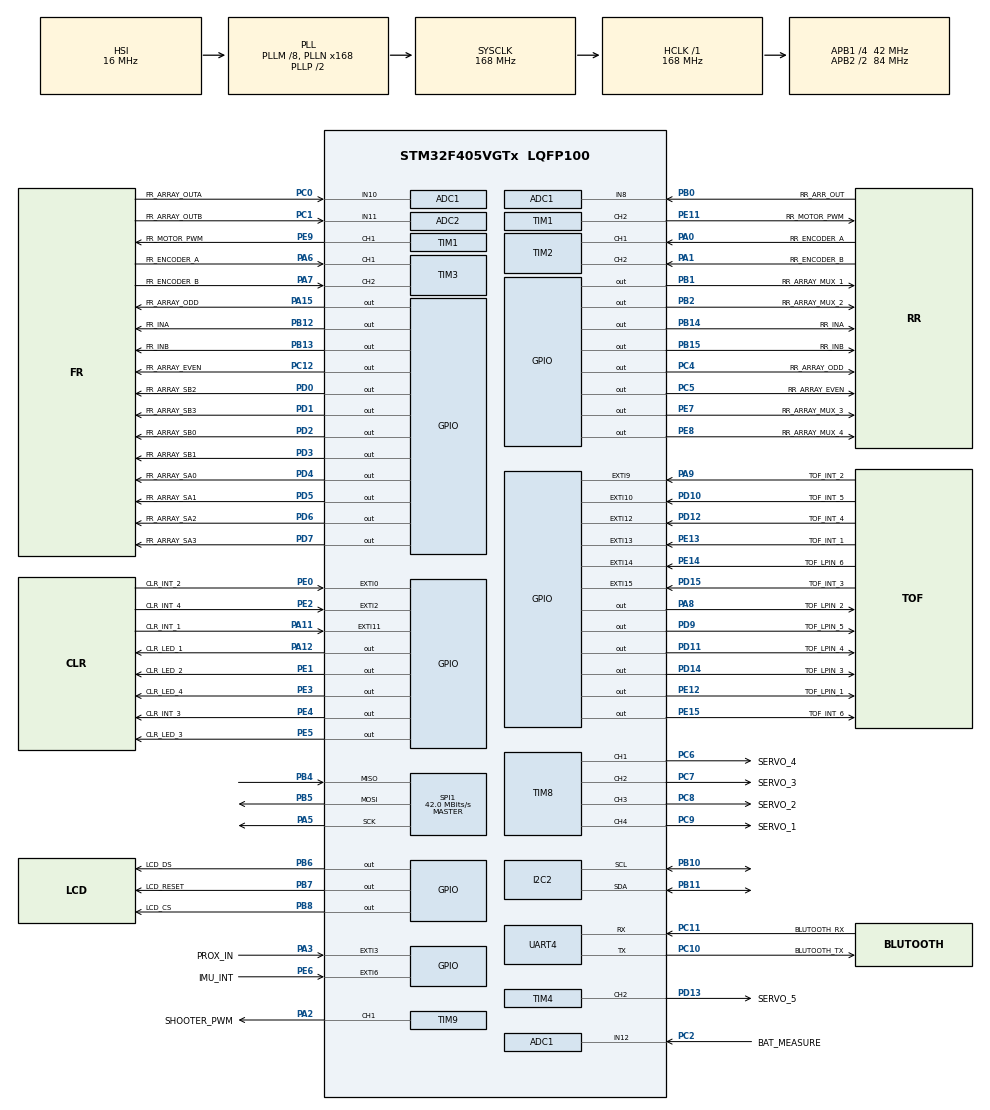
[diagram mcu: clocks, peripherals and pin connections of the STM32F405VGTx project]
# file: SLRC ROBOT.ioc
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ADC1.Channel-1\#ChannelRegularConversion=ADC_CHANNEL_8
ADC1.NbrOfConversionFlag=1
ADC1.Rank-1\#ChannelRegularConversion=1
ADC1.SamplingTime-1\#ChannelRegularConversion=ADC_SAMPLETIME_3CYCLES
ADC1.master=1
ADC2.Channel-1\#ChannelRegularConversion=ADC_CHANNEL_11
ADC2.NbrOfConversionFlag=1
ADC2.Rank-1\#ChannelRegularConversion=1
ADC2.SamplingTime-1\#ChannelRegularConversion=ADC_SAMPLETIME_3CYCLES
Mcu.Family=STM32F4
Mcu.Name=STM32F405VGTx
Mcu.Package=LQFP100
NVIC.PriorityGroup=NVIC_PRIORITYGROUP_4
PA0-WKUP.GPIO_Label=RR_ENCODER_A
PA0-WKUP.Signal=S_TIM2_CH1_ETR
PA1.GPIO_Label=RR_ENCODER_B
PA1.Signal=S_TIM2_CH2
PA11.GPIO_Label=CLR_INT_1
PA11.Signal=GPXTI11
PA12.GPIO_Label=CLR_LED_1
PA12.Signal=GPIO_Output
PA13.Mode=Trace_Asynchronous_SW
PA13.Signal=SYS_JTMS-SWDIO
PA14.Mode=Trace_Asynchronous_SW
PA14.Signal=SYS_JTCK-SWCLK
PA15.GPIO_Label=FR_ARRAY_ODD
PA15.Signal=GPIO_Output
PA2.GPIO_Label=SHOOTER_PWM
PA2.Signal=S_TIM9_CH1
PA3.GPIO_Label=PROX_IN
PA3.Signal=GPXTI3
PA5.Mode=Full_Duplex_Master
PA5.Signal=SPI1_SCK
PA6.GPIO_Label=FR_ENCODER_A
PA6.Signal=S_TIM3_CH1
PA7.GPIO_Label=FR_ENCODER_B
PA7.Signal=S_TIM3_CH2
PA8.GPIO_Label=TOF_LPIN_2
PA8.Signal=GPIO_Output
PA9.GPIO_Label=TOF_INT_2
PA9.Signal=GPXTI9
PB0.GPIO_Label=RR_ARR_OUT
PB0.Signal=ADCx_IN8
PB1.GPIO_Label=RR_ARRAY_MUX_1
PB1.Signal=GPIO_Output
PB10.GPIO_Pu=GPIO_PULLUP
PB10.Mode=I2C
PB10.Signal=I2C2_SCL
PB11.GPIO_Pu=GPIO_PULLUP
PB11.Mode=I2C
PB11.Signal=I2C2_SDA
PB12.GPIO_Label=FR_INA
PB12.Signal=GPIO_Output
PB13.GPIO_Label=FR_INB
PB13.Signal=GPIO_Output
PB14.GPIO_Label=RR_INA
PB14.Signal=GPIO_Output
PB15.GPIO_Label=RR_INB
PB15.Signal=GPIO_Output
PB2.GPIO_Label=RR_ARRAY_MUX_2
PB2.Signal=GPIO_Output
PB3.Mode=Trace_Asynchronous_SW
PB3.Signal=SYS_JTDO-SWO
PB4.Mode=Full_Duplex_Master
PB4.Signal=SPI1_MISO
PB5.Mode=Full_Duplex_Master
PB5.Signal=SPI1_MOSI
PB6.GPIO_Label=LCD_DS
PB6.Signal=GPIO_Output
PB7.GPIO_Label=LCD_RESET
PB7.Signal=GPIO_Output
PB8.GPIO_Label=LCD_CS
PB8.Signal=GPIO_Output
PC0.GPIO_Label=FR_ARRAY_OUTA
PC0.Signal=ADCx_IN10
PC1.GPIO_Label=FR_ARRAY_OUTB
PC1.Signal=ADCx_IN11
PC10.GPIO_Label=BLUTOOTH_TX
PC10.Mode=Asynchronous
PC10.Signal=UART4_TX
PC11.GPIO_Label=BLUTOOTH_RX
PC11.Mode=Asynchronous
PC11.Signal=UART4_RX
PC12.GPIO_Label=FR_ARRAY_EVEN
PC12.Signal=GPIO_Output
PC2.GPIO_Label=BAT_MEASURE
PC2.Signal=ADCx_IN12
PC4.GPIO_Label=RR_ARRAY_ODD
PC4.Signal=GPIO_Output
PC5.GPIO_Label=RR_ARRAY_EVEN
PC5.Signal=GPIO_Output
PC6.GPIO_Label=SERVO_4
PC6.Signal=S_TIM8_CH1
PC7.GPIO_Label=SERVO_3
PC7.Signal=S_TIM8_CH2
PC8.GPIO_Label=SERVO_2
PC8.Signal=S_TIM8_CH3
PC9.GPIO_Label=SERVO_1
PC9.Signal=S_TIM8_CH4
PD0.GPIO_Label=FR_ARRAY_SB2
PD0.Signal=GPIO_Output
PD1.GPIO_Label=FR_ARRAY_SB3
PD1.Signal=GPIO_Output
PD10.GPIO_Label=TOF_INT_5
PD10.Signal=GPXTI10
PD11.GPIO_Label=TOF_LPIN_4
PD11.Signal=GPIO_Output
PD12.GPIO_Label=TOF_INT_4
PD12.Signal=GPXTI12
PD13.GPIO_Label=SERVO_5
PD13.Signal=S_TIM4_CH2
PD14.GPIO_Label=TOF_LPIN_3
PD14.Signal=GPIO_Output
PD15.GPIO_Label=TOF_INT_3
PD15.Signal=GPXTI15
PD2.GPIO_Label=FR_ARRAY_SB0
PD2.Signal=GPIO_Output
PD3.GPIO_Label=FR_ARRAY_SB1
PD3.Signal=GPIO_Output
PD4.GPIO_Label=FR_ARRAY_SA0
PD4.Signal=GPIO_Output
PD5.GPIO_Label=FR_ARRAY_SA1
PD5.Signal=GPIO_Output
PD6.GPIO_Label=FR_ARRAY_SA2
PD6.Signal=GPIO_Output
PD7.GPIO_Label=FR_ARRAY_SA3
PD7.Signal=GPIO_Output
PD9.GPIO_Label=TOF_LPIN_5
PD9.Signal=GPIO_Output
PE0.GPIO_Label=CLR_INT_2
PE0.Signal=GPXTI0
PE1.GPIO_Label=CLR_LED_2
PE1.Signal=GPIO_Output
PE11.GPIO_Label=RR_MOTOR_PWM
PE11.Signal=S_TIM1_CH2
PE12.GPIO_Label=TOF_LPIN_1
PE12.Signal=GPIO_Output
PE13.GPIO_Label=TOF_INT_1
PE13.Signal=GPXTI13
PE14.GPIO_Label=TOF_LPIN_6
PE14.Signal=GPXTI14
PE15.GPIO_Label=TOF_INT_6
PE15.Signal=GPIO_Output
PE2.GPIO_Label=CLR_INT_4
PE2.Signal=GPXTI2
PE3.GPIO_Label=CLR_LED_4
PE3.Signal=GPIO_Output
PE4.GPIO_Label=CLR_INT_3
PE4.Signal=GPIO_Output
PE5.GPIO_Label=CLR_LED_3
PE5.Signal=GPIO_Output
PE6.GPIO_Label=IMU_INT
PE6.Signal=GPXTI6
PE7.GPIO_Label=RR_ARRAY_MUX_3
PE7.Signal=GPIO_Output
PE8.GPIO_Label=RR_ARRAY_MUX_4
PE8.Signal=GPIO_Output
PE9.GPIO_Label=FR_MOTOR_PWM
PE9.Signal=S_TIM1_CH1
PH0-OSC_IN.Mode=HSE-External-Oscillator
PH0-OSC_IN.Signal=RCC_OSC_IN
PH1-OSC_OUT.Mode=HSE-External-Oscillator
PH1-OSC_OUT.Signal=RCC_OSC_OUT
ProjectManager.HeapSize=0x200
ProjectManager.StackSize=0x400
ProjectManager.TargetToolchain=STM32CubeIDE
RCC.48MHZClocksFreq_Value=84000000
RCC.AHBFreq_Value=168000000
RCC.APB1CLKDivider=RCC_HCLK_DIV4
RCC.APB1Freq_Value=42000000
RCC.APB1TimFreq_Value=84000000
RCC.APB2CLKDivider=RCC_HCLK_DIV2
RCC.APB2Freq_Value=84000000
RCC.APB2TimFreq_Value=168000000
RCC.CortexFreq_Value=168000000
RCC.HCLKFreq_Value=168000000
RCC.HSE_VALUE=24000000
RCC.HSI_VALUE=16000000
RCC.LSE_VALUE=32768
RCC.PLLM=8
RCC.PLLN=168
RCC.SYSCLKFreq_VALUE=168000000
RCC.SYSCLKSource=RCC_SYSCLKSOURCE_PLLCLK
RCC.VCOOutputFreq_Value=336000000
SH.ADCx_IN10.0=ADC1_IN10,IN10
SH.ADCx_IN11.0=ADC2_IN11,IN11
SH.ADCx_IN12.0=ADC1_IN12,IN12
SH.ADCx_IN8.0=ADC1_IN8,IN8
SH.S_TIM1_CH1.0=TIM1_CH1,PWM Generation1 CH1
SH.S_TIM1_CH2.0=TIM1_CH2,PWM Generation2 CH2
SH.S_TIM2_CH1_ETR.0=TIM2_CH1,Encoder_Interface
SH.S_TIM2_CH2.0=TIM2_CH2,Encoder_Interface
SH.S_TIM3_CH1.0=TIM3_CH1,Encoder_Interface
SH.S_TIM3_CH2.0=TIM3_CH2,Encoder_Interface
SH.S_TIM4_CH2.0=TIM4_CH2,PWM Generation2 CH2
SH.S_TIM8_CH1.0=TIM8_CH1,PWM Generation1 CH1
SH.S_TIM8_CH2.0=TIM8_CH2,PWM Generation2 CH2
SH.S_TIM8_CH3.0=TIM8_CH3,PWM Generation3 CH3
SH.S_TIM8_CH4.0=TIM8_CH4,PWM Generation4 CH4
SH.S_TIM9_CH1.0=TIM9_CH1,PWM Generation1 CH1
SPI1.CalculateBaudRate=42.0 MBits/s
SPI1.Direction=SPI_DIRECTION_2LINES
SPI1.Mode=SPI_MODE_MASTER
SPI1.VirtualType=VM_MASTER
TIM1.Channel-PWM\ Generation1\ CH1=TIM_CHANNEL_1
TIM1.Channel-PWM\ Generation2\ CH2=TIM_CHANNEL_2
TIM3.EncoderMode=TIM_ENCODERMODE_TI12
TIM4.Channel-PWM\ Generation2\ CH2=TIM_CHANNEL_2
TIM8.Channel-PWM\ Generation1\ CH1=TIM_CHANNEL_1
TIM8.Channel-PWM\ Generation2\ CH2=TIM_CHANNEL_2
TIM8.Channel-PWM\ Generation3\ CH3=TIM_CHANNEL_3
TIM8.Channel-PWM\ Generation4\ CH4=TIM_CHANNEL_4
TIM9.Channel-PWM\ Generation1\ CH1=TIM_CHANNEL_1
UART4.VirtualMode=Asynchronous
VP_TIM1_VS_ClockSourceINT.Mode=Internal
VP_TIM4_VS_ClockSourceINT.Mode=Internal
VP_TIM8_VS_ClockSourceINT.Mode=Internal
VP_TIM9_VS_ClockSourceINT.Mode=Internal
board=custom

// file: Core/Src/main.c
/* USER CODE BEGIN Header */
/**
  ******************************************************************************
  * @file           : main.c
  * @brief          : Main program body
  ******************************************************************************
  * @attention
  *
  * Copyright (c) 2024 STMicroelectronics.
  * All rights reserved.
  *
  * This software is licensed under terms that can be found in the LICENSE file
  * in the root directory of this software component.
  * If no LICENSE file comes with this software, it is provided AS-IS.
  *
  ******************************************************************************
  */
/* USER CODE END Header */
#include "main.h"

/* USER CODE BEGIN Includes */
#include "TPS55288.h"
#include "stm32f4xx_hal.h"
/* USER CODE END Includes */

ADC_HandleTypeDef hadc1;
ADC_HandleTypeDef hadc2;

I2C_HandleTypeDef hi2c2;

SPI_HandleTypeDef hspi1;

TIM_HandleTypeDef htim1;
TIM_HandleTypeDef htim2;
TIM_HandleTypeDef htim3;
TIM_HandleTypeDef htim4;
TIM_HandleTypeDef htim8;
TIM_HandleTypeDef htim9;

UART_HandleTypeDef huart4;

/* USER CODE BEGIN PV */
TPS55288 BuckBoost;
HAL_StatusTypeDef result;
uint8_t TX_Buffer [] = "A" ; // DATA to send
/* USER CODE END PV */

void SystemClock_Config(void);
static void MX_GPIO_Init(void);
static void MX_ADC1_Init(void);
static void MX_I2C2_Init(void);
static void MX_TIM1_Init(void);
static void MX_TIM3_Init(void);
static void MX_TIM4_Init(void);
static void MX_TIM8_Init(void);
static void MX_TIM9_Init(void);
static void MX_UART4_Init(void);
static void MX_SPI1_Init(void);
static void MX_ADC2_Init(void);
static void MX_TIM2_Init(void);

int main(void)
{

  /* MCU Configuration--------------------------------------------------------*/

  /* Reset of all peripherals, Initializes the Flash interface and the Systick. */
  HAL_Init();

  /* Configure the system clock */
  SystemClock_Config();

  /* Initialize all configured peripherals */
  MX_GPIO_Init();
  MX_ADC1_Init();
  MX_I2C2_Init();
  MX_TIM1_Init();
  MX_TIM3_Init();
  MX_TIM4_Init();
  MX_TIM8_Init();
  MX_TIM9_Init();
  MX_UART4_Init();
  MX_SPI1_Init();
  MX_ADC2_Init();
  MX_TIM2_Init();
  /* USER CODE BEGIN 2 */

#define ADDRESS_TO 0x40

  /* USER CODE END 2 */

  /* Infinite loop */
  while (1)
  {

    /* USER CODE BEGIN 3 */
//	  uint8_t status = TPS55288_Initialize(&BuckBoost, &hi2c2);
	  uint8_t command;
	  uint8_t config;
	  uint8_t output;
	  command = 0x03;
	  config = 0x00;
//	  HAL_I2C_Mem_Write(&hi2c2, ADDRESS_TO, command, 1, &config, 1, 10);
//	  HAL_I2C_Mem_Write(&hi2c2,TPS55288_I2C_ADDR,command,1,&config, 1 ,10); //Sending in Blocking mode
 // for the return value from HAL function calls

		result = HAL_I2C_IsDeviceReady( &hi2c2, 0x40<<1, 10, 1000 );
	  HAL_Delay(100);
	  HAL_GPIO_WritePin(CLR_LED_3_GPIO_Port, CLR_LED_3_Pin, GPIO_PIN_SET);
	  HAL_Delay(1500);
	  HAL_GPIO_WritePin(CLR_LED_3_GPIO_Port, CLR_LED_3_Pin, GPIO_PIN_RESET);
	  HAL_Delay(1500);
  }
  /* USER CODE END 3 */
}

void SystemClock_Config(void)
{
  RCC_OscInitTypeDef RCC_OscInitStruct = {0};
  RCC_ClkInitTypeDef RCC_ClkInitStruct = {0};

  /** Configure the main internal regulator output voltage
  */
  __HAL_RCC_PWR_CLK_ENABLE();
  __HAL_PWR_VOLTAGESCALING_CONFIG(PWR_REGULATOR_VOLTAGE_SCALE1);

  /** Initializes the RCC Oscillators according to the specified parameters
  * in the RCC_OscInitTypeDef structure.
  */
  RCC_OscInitStruct.OscillatorType = RCC_OSCILLATORTYPE_HSI;
  RCC_OscInitStruct.HSIState = RCC_HSI_ON;
  RCC_OscInitStruct.HSICalibrationValue = RCC_HSICALIBRATION_DEFAULT;
  RCC_OscInitStruct.PLL.PLLState = RCC_PLL_ON;
  RCC_OscInitStruct.PLL.PLLSource = RCC_PLLSOURCE_HSI;
  RCC_OscInitStruct.PLL.PLLM = 8;
  RCC_OscInitStruct.PLL.PLLN = 168;
  RCC_OscInitStruct.PLL.PLLP = RCC_PLLP_DIV2;
  RCC_OscInitStruct.PLL.PLLQ = 4;
  if (HAL_RCC_OscConfig(&RCC_OscInitStruct) != HAL_OK)
  {
    Error_Handler();
  }

  /** Initializes the CPU, AHB and APB buses clocks
  */
  RCC_ClkInitStruct.ClockType = RCC_CLOCKTYPE_HCLK|RCC_CLOCKTYPE_SYSCLK
                              |RCC_CLOCKTYPE_PCLK1|RCC_CLOCKTYPE_PCLK2;
  RCC_ClkInitStruct.SYSCLKSource = RCC_SYSCLKSOURCE_PLLCLK;
  RCC_ClkInitStruct.AHBCLKDivider = RCC_SYSCLK_DIV1;
  RCC_ClkInitStruct.APB1CLKDivider = RCC_HCLK_DIV4;
  RCC_ClkInitStruct.APB2CLKDivider = RCC_HCLK_DIV2;

  if (HAL_RCC_ClockConfig(&RCC_ClkInitStruct, FLASH_LATENCY_5) != HAL_OK)
  {
    Error_Handler();
  }
}

static void MX_ADC1_Init(void)
{

  ADC_ChannelConfTypeDef sConfig = {0};

  /** Configure the global features of the ADC (Clock, Resolution, Data Alignment and number of conversion)
  */
  hadc1.Instance = ADC1;
  hadc1.Init.ClockPrescaler = ADC_CLOCK_SYNC_PCLK_DIV4;
  hadc1.Init.Resolution = ADC_RESOLUTION_12B;
  hadc1.Init.ScanConvMode = DISABLE;
  hadc1.Init.ContinuousConvMode = DISABLE;
  hadc1.Init.DiscontinuousConvMode = DISABLE;
  hadc1.Init.ExternalTrigConvEdge = ADC_EXTERNALTRIGCONVEDGE_NONE;
  hadc1.Init.ExternalTrigConv = ADC_SOFTWARE_START;
  hadc1.Init.DataAlign = ADC_DATAALIGN_RIGHT;
  hadc1.Init.NbrOfConversion = 1;
  hadc1.Init.DMAContinuousRequests = DISABLE;
  hadc1.Init.EOCSelection = ADC_EOC_SINGLE_CONV;
  if (HAL_ADC_Init(&hadc1) != HAL_OK)
  {
    Error_Handler();
  }

  /** Configure for the selected ADC regular channel its corresponding rank in the sequencer and its sample time.
  */
  sConfig.Channel = ADC_CHANNEL_8;
  sConfig.Rank = 1;
  sConfig.SamplingTime = ADC_SAMPLETIME_3CYCLES;
  if (HAL_ADC_ConfigChannel(&hadc1, &sConfig) != HAL_OK)
  {
    Error_Handler();
  }

}

static void MX_ADC2_Init(void)
{

  ADC_ChannelConfTypeDef sConfig = {0};

  /** Configure the global features of the ADC (Clock, Resolution, Data Alignment and number of conversion)
  */
  hadc2.Instance = ADC2;
  hadc2.Init.ClockPrescaler = ADC_CLOCK_SYNC_PCLK_DIV4;
  hadc2.Init.Resolution = ADC_RESOLUTION_12B;
  hadc2.Init.ScanConvMode = DISABLE;
  hadc2.Init.ContinuousConvMode = DISABLE;
  hadc2.Init.DiscontinuousConvMode = DISABLE;
  hadc2.Init.ExternalTrigConvEdge = ADC_EXTERNALTRIGCONVEDGE_NONE;
  hadc2.Init.ExternalTrigConv = ADC_SOFTWARE_START;
  hadc2.Init.DataAlign = ADC_DATAALIGN_RIGHT;
  hadc2.Init.NbrOfConversion = 1;
  hadc2.Init.DMAContinuousRequests = DISABLE;
  hadc2.Init.EOCSelection = ADC_EOC_SINGLE_CONV;
  if (HAL_ADC_Init(&hadc2) != HAL_OK)
  {
    Error_Handler();
  }

  /** Configure for the selected ADC regular channel its corresponding rank in the sequencer and its sample time.
  */
  sConfig.Channel = ADC_CHANNEL_11;
  sConfig.Rank = 1;
  sConfig.SamplingTime = ADC_SAMPLETIME_3CYCLES;
  if (HAL_ADC_ConfigChannel(&hadc2, &sConfig) != HAL_OK)
  {
    Error_Handler();
  }

}

static void MX_I2C2_Init(void)
{

  hi2c2.Instance = I2C2;
  hi2c2.Init.ClockSpeed = 100000;
  hi2c2.Init.DutyCycle = I2C_DUTYCYCLE_2;
  hi2c2.Init.OwnAddress1 = 0;
  hi2c2.Init.AddressingMode = I2C_ADDRESSINGMODE_7BIT;
  hi2c2.Init.DualAddressMode = I2C_DUALADDRESS_DISABLE;
  hi2c2.Init.OwnAddress2 = 0;
  hi2c2.Init.GeneralCallMode = I2C_GENERALCALL_DISABLE;
  hi2c2.Init.NoStretchMode = I2C_NOSTRETCH_DISABLE;
  if (HAL_I2C_Init(&hi2c2) != HAL_OK)
  {
    Error_Handler();
  }

}

static void MX_SPI1_Init(void)
{

  /* SPI1 parameter configuration*/
  hspi1.Instance = SPI1;
  hspi1.Init.Mode = SPI_MODE_MASTER;
  hspi1.Init.Direction = SPI_DIRECTION_2LINES;
  hspi1.Init.DataSize = SPI_DATASIZE_8BIT;
  hspi1.Init.CLKPolarity = SPI_POLARITY_LOW;
  hspi1.Init.CLKPhase = SPI_PHASE_1EDGE;
  hspi1.Init.NSS = SPI_NSS_SOFT;
  hspi1.Init.BaudRatePrescaler = SPI_BAUDRATEPRESCALER_2;
  hspi1.Init.FirstBit = SPI_FIRSTBIT_MSB;
  hspi1.Init.TIMode = SPI_TIMODE_DISABLE;
  hspi1.Init.CRCCalculation = SPI_CRCCALCULATION_DISABLE;
  hspi1.Init.CRCPolynomial = 10;
  if (HAL_SPI_Init(&hspi1) != HAL_OK)
  {
    Error_Handler();
  }

}

static void MX_TIM1_Init(void)
{

  TIM_ClockConfigTypeDef sClockSourceConfig = {0};
  TIM_MasterConfigTypeDef sMasterConfig = {0};
  TIM_OC_InitTypeDef sConfigOC = {0};
  TIM_BreakDeadTimeConfigTypeDef sBreakDeadTimeConfig = {0};

  htim1.Instance = TIM1;
  htim1.Init.Prescaler = 0;
  htim1.Init.CounterMode = TIM_COUNTERMODE_UP;
  htim1.Init.Period = 65535;
  htim1.Init.ClockDivision = TIM_CLOCKDIVISION_DIV1;
  htim1.Init.RepetitionCounter = 0;
  htim1.Init.AutoReloadPreload = TIM_AUTORELOAD_PRELOAD_DISABLE;
  if (HAL_TIM_Base_Init(&htim1) != HAL_OK)
  {
    Error_Handler();
  }
  sClockSourceConfig.ClockSource = TIM_CLOCKSOURCE_INTERNAL;
  if (HAL_TIM_ConfigClockSource(&htim1, &sClockSourceConfig) != HAL_OK)
  {
    Error_Handler();
  }
  if (HAL_TIM_PWM_Init(&htim1) != HAL_OK)
  {
    Error_Handler();
  }
  sMasterConfig.MasterOutputTrigger = TIM_TRGO_RESET;
  sMasterConfig.MasterSlaveMode = TIM_MASTERSLAVEMODE_DISABLE;
  if (HAL_TIMEx_MasterConfigSynchronization(&htim1, &sMasterConfig) != HAL_OK)
  {
    Error_Handler();
  }
  sConfigOC.OCMode = TIM_OCMODE_PWM1;
  sConfigOC.Pulse = 0;
  sConfigOC.OCPolarity = TIM_OCPOLARITY_HIGH;
  sConfigOC.OCNPolarity = TIM_OCNPOLARITY_HIGH;
  sConfigOC.OCFastMode = TIM_OCFAST_DISABLE;
  sConfigOC.OCIdleState = TIM_OCIDLESTATE_RESET;
  sConfigOC.OCNIdleState = TIM_OCNIDLESTATE_RESET;
  if (HAL_TIM_PWM_ConfigChannel(&htim1, &sConfigOC, TIM_CHANNEL_1) != HAL_OK)
  {
    Error_Handler();
  }
  if (HAL_TIM_PWM_ConfigChannel(&htim1, &sConfigOC, TIM_CHANNEL_2) != HAL_OK)
  {
    Error_Handler();
  }
  sBreakDeadTimeConfig.OffStateRunMode = TIM_OSSR_DISABLE;
  sBreakDeadTimeConfig.OffStateIDLEMode = TIM_OSSI_DISABLE;
  sBreakDeadTimeConfig.LockLevel = TIM_LOCKLEVEL_OFF;
  sBreakDeadTimeConfig.DeadTime = 0;
  sBreakDeadTimeConfig.BreakState = TIM_BREAK_DISABLE;
  sBreakDeadTimeConfig.BreakPolarity = TIM_BREAKPOLARITY_HIGH;
  sBreakDeadTimeConfig.AutomaticOutput = TIM_AUTOMATICOUTPUT_DISABLE;
  if (HAL_TIMEx_ConfigBreakDeadTime(&htim1, &sBreakDeadTimeConfig) != HAL_OK)
  {
    Error_Handler();
  }
  HAL_TIM_MspPostInit(&htim1);

}

static void MX_TIM2_Init(void)
{

  TIM_Encoder_InitTypeDef sConfig = {0};
  TIM_MasterConfigTypeDef sMasterConfig = {0};

  htim2.Instance = TIM2;
  htim2.Init.Prescaler = 0;
  htim2.Init.CounterMode = TIM_COUNTERMODE_UP;
  htim2.Init.Period = 4294967295;
  htim2.Init.ClockDivision = TIM_CLOCKDIVISION_DIV1;
  htim2.Init.AutoReloadPreload = TIM_AUTORELOAD_PRELOAD_DISABLE;
  sConfig.EncoderMode = TIM_ENCODERMODE_TI1;
  sConfig.IC1Polarity = TIM_ICPOLARITY_RISING;
  sConfig.IC1Selection = TIM_ICSELECTION_DIRECTTI;
  sConfig.IC1Prescaler = TIM_ICPSC_DIV1;
  sConfig.IC1Filter = 0;
  sConfig.IC2Polarity = TIM_ICPOLARITY_RISING;
  sConfig.IC2Selection = TIM_ICSELECTION_DIRECTTI;
  sConfig.IC2Prescaler = TIM_ICPSC_DIV1;
  sConfig.IC2Filter = 0;
  if (HAL_TIM_Encoder_Init(&htim2, &sConfig) != HAL_OK)
  {
    Error_Handler();
  }
  sMasterConfig.MasterOutputTrigger = TIM_TRGO_RESET;
  sMasterConfig.MasterSlaveMode = TIM_MASTERSLAVEMODE_DISABLE;
  if (HAL_TIMEx_MasterConfigSynchronization(&htim2, &sMasterConfig) != HAL_OK)
  {
    Error_Handler();
  }

}

static void MX_TIM3_Init(void)
{

  TIM_Encoder_InitTypeDef sConfig = {0};
  TIM_MasterConfigTypeDef sMasterConfig = {0};

  htim3.Instance = TIM3;
  htim3.Init.Prescaler = 0;
  htim3.Init.CounterMode = TIM_COUNTERMODE_UP;
  htim3.Init.Period = 65535;
  htim3.Init.ClockDivision = TIM_CLOCKDIVISION_DIV1;
  htim3.Init.AutoReloadPreload = TIM_AUTORELOAD_PRELOAD_DISABLE;
  sConfig.EncoderMode = TIM_ENCODERMODE_TI12;
  sConfig.IC1Polarity = TIM_ICPOLARITY_RISING;
  sConfig.IC1Selection = TIM_ICSELECTION_DIRECTTI;
  sConfig.IC1Prescaler = TIM_ICPSC_DIV1;
  sConfig.IC1Filter = 0;
  sConfig.IC2Polarity = TIM_ICPOLARITY_RISING;
  sConfig.IC2Selection = TIM_ICSELECTION_DIRECTTI;
  sConfig.IC2Prescaler = TIM_ICPSC_DIV1;
  sConfig.IC2Filter = 0;
  if (HAL_TIM_Encoder_Init(&htim3, &sConfig) != HAL_OK)
  {
    Error_Handler();
  }
  sMasterConfig.MasterOutputTrigger = TIM_TRGO_RESET;
  sMasterConfig.MasterSlaveMode = TIM_MASTERSLAVEMODE_DISABLE;
  if (HAL_TIMEx_MasterConfigSynchronization(&htim3, &sMasterConfig) != HAL_OK)
  {
    Error_Handler();
  }

}

static void MX_TIM4_Init(void)
{

  TIM_ClockConfigTypeDef sClockSourceConfig = {0};
  TIM_MasterConfigTypeDef sMasterConfig = {0};
  TIM_OC_InitTypeDef sConfigOC = {0};

  htim4.Instance = TIM4;
  htim4.Init.Prescaler = 0;
  htim4.Init.CounterMode = TIM_COUNTERMODE_UP;
  htim4.Init.Period = 65535;
  htim4.Init.ClockDivision = TIM_CLOCKDIVISION_DIV1;
  htim4.Init.AutoReloadPreload = TIM_AUTORELOAD_PRELOAD_DISABLE;
  if (HAL_TIM_Base_Init(&htim4) != HAL_OK)
  {
    Error_Handler();
  }
  sClockSourceConfig.ClockSource = TIM_CLOCKSOURCE_INTERNAL;
  if (HAL_TIM_ConfigClockSource(&htim4, &sClockSourceConfig) != HAL_OK)
  {
    Error_Handler();
  }
  if (HAL_TIM_PWM_Init(&htim4) != HAL_OK)
  {
    Error_Handler();
  }
  sMasterConfig.MasterOutputTrigger = TIM_TRGO_RESET;
  sMasterConfig.MasterSlaveMode = TIM_MASTERSLAVEMODE_DISABLE;
  if (HAL_TIMEx_MasterConfigSynchronization(&htim4, &sMasterConfig) != HAL_OK)
  {
    Error_Handler();
  }
  sConfigOC.OCMode = TIM_OCMODE_PWM1;
  sConfigOC.Pulse = 0;
  sConfigOC.OCPolarity = TIM_OCPOLARITY_HIGH;
  sConfigOC.OCFastMode = TIM_OCFAST_DISABLE;
  if (HAL_TIM_PWM_ConfigChannel(&htim4, &sConfigOC, TIM_CHANNEL_2) != HAL_OK)
  {
    Error_Handler();
  }
  HAL_TIM_MspPostInit(&htim4);

}

static void MX_TIM8_Init(void)
{

  TIM_ClockConfigTypeDef sClockSourceConfig = {0};
  TIM_MasterConfigTypeDef sMasterConfig = {0};
  TIM_OC_InitTypeDef sConfigOC = {0};
  TIM_BreakDeadTimeConfigTypeDef sBreakDeadTimeConfig = {0};

  htim8.Instance = TIM8;
  htim8.Init.Prescaler = 0;
  htim8.Init.CounterMode = TIM_COUNTERMODE_UP;
  htim8.Init.Period = 65535;
  htim8.Init.ClockDivision = TIM_CLOCKDIVISION_DIV1;
  htim8.Init.RepetitionCounter = 0;
  htim8.Init.AutoReloadPreload = TIM_AUTORELOAD_PRELOAD_DISABLE;
  if (HAL_TIM_Base_Init(&htim8) != HAL_OK)
  {
    Error_Handler();
  }
  sClockSourceConfig.ClockSource = TIM_CLOCKSOURCE_INTERNAL;
  if (HAL_TIM_ConfigClockSource(&htim8, &sClockSourceConfig) != HAL_OK)
  {
    Error_Handler();
  }
  if (HAL_TIM_PWM_Init(&htim8) != HAL_OK)
  {
    Error_Handler();
  }
  sMasterConfig.MasterOutputTrigger = TIM_TRGO_RESET;
  sMasterConfig.MasterSlaveMode = TIM_MASTERSLAVEMODE_DISABLE;
  if (HAL_TIMEx_MasterConfigSynchronization(&htim8, &sMasterConfig) != HAL_OK)
  {
    Error_Handler();
  }
  sConfigOC.OCMode = TIM_OCMODE_PWM1;
  sConfigOC.Pulse = 0;
  sConfigOC.OCPolarity = TIM_OCPOLARITY_HIGH;
  sConfigOC.OCNPolarity = TIM_OCNPOLARITY_HIGH;
  sConfigOC.OCFastMode = TIM_OCFAST_DISABLE;
  sConfigOC.OCIdleState = TIM_OCIDLESTATE_RESET;
  sConfigOC.OCNIdleState = TIM_OCNIDLESTATE_RESET;
  if (HAL_TIM_PWM_ConfigChannel(&htim8, &sConfigOC, TIM_CHANNEL_1) != HAL_OK)
  {
    Error_Handler();
  }
  if (HAL_TIM_PWM_ConfigChannel(&htim8, &sConfigOC, TIM_CHANNEL_2) != HAL_OK)
  {
    Error_Handler();
  }
  if (HAL_TIM_PWM_ConfigChannel(&htim8, &sConfigOC, TIM_CHANNEL_3) != HAL_OK)
  {
    Error_Handler();
  }
  if (HAL_TIM_PWM_ConfigChannel(&htim8, &sConfigOC, TIM_CHANNEL_4) != HAL_OK)
  {
    Error_Handler();
  }
  sBreakDeadTimeConfig.OffStateRunMode = TIM_OSSR_DISABLE;
  sBreakDeadTimeConfig.OffStateIDLEMode = TIM_OSSI_DISABLE;
  sBreakDeadTimeConfig.LockLevel = TIM_LOCKLEVEL_OFF;
  sBreakDeadTimeConfig.DeadTime = 0;
  sBreakDeadTimeConfig.BreakState = TIM_BREAK_DISABLE;
  sBreakDeadTimeConfig.BreakPolarity = TIM_BREAKPOLARITY_HIGH;
  sBreakDeadTimeConfig.AutomaticOutput = TIM_AUTOMATICOUTPUT_DISABLE;
  if (HAL_TIMEx_ConfigBreakDeadTime(&htim8, &sBreakDeadTimeConfig) != HAL_OK)
  {
    Error_Handler();
  }
  HAL_TIM_MspPostInit(&htim8);

}

static void MX_TIM9_Init(void)
{

  TIM_ClockConfigTypeDef sClockSourceConfig = {0};
  TIM_OC_InitTypeDef sConfigOC = {0};

  htim9.Instance = TIM9;
  htim9.Init.Prescaler = 0;
  htim9.Init.CounterMode = TIM_COUNTERMODE_UP;
  htim9.Init.Period = 65535;
  htim9.Init.ClockDivision = TIM_CLOCKDIVISION_DIV1;
  htim9.Init.AutoReloadPreload = TIM_AUTORELOAD_PRELOAD_DISABLE;
  if (HAL_TIM_Base_Init(&htim9) != HAL_OK)
  {
    Error_Handler();
  }
  sClockSourceConfig.ClockSource = TIM_CLOCKSOURCE_INTERNAL;
  if (HAL_TIM_ConfigClockSource(&htim9, &sClockSourceConfig) != HAL_OK)
  {
    Error_Handler();
  }
  if (HAL_TIM_PWM_Init(&htim9) != HAL_OK)
  {
    Error_Handler();
  }
  sConfigOC.OCMode = TIM_OCMODE_PWM1;
  sConfigOC.Pulse = 0;
  sConfigOC.OCPolarity = TIM_OCPOLARITY_HIGH;
  sConfigOC.OCFastMode = TIM_OCFAST_DISABLE;
  if (HAL_TIM_PWM_ConfigChannel(&htim9, &sConfigOC, TIM_CHANNEL_1) != HAL_OK)
  {
    Error_Handler();
  }
  HAL_TIM_MspPostInit(&htim9);

}

static void MX_UART4_Init(void)
{

  huart4.Instance = UART4;
  huart4.Init.BaudRate = 115200;
  huart4.Init.WordLength = UART_WORDLENGTH_8B;
  huart4.Init.StopBits = UART_STOPBITS_1;
  huart4.Init.Parity = UART_PARITY_NONE;
  huart4.Init.Mode = UART_MODE_TX_RX;
  huart4.Init.HwFlowCtl = UART_HWCONTROL_NONE;
  huart4.Init.OverSampling = UART_OVERSAMPLING_16;
  if (HAL_UART_Init(&huart4) != HAL_OK)
  {
    Error_Handler();
  }

}

static void MX_GPIO_Init(void)
{
  GPIO_InitTypeDef GPIO_InitStruct = {0};

  /* GPIO Ports Clock Enable */
  __HAL_RCC_GPIOE_CLK_ENABLE();
  __HAL_RCC_GPIOH_CLK_ENABLE();
  __HAL_RCC_GPIOC_CLK_ENABLE();
  __HAL_RCC_GPIOA_CLK_ENABLE();
  __HAL_RCC_GPIOB_CLK_ENABLE();
  __HAL_RCC_GPIOD_CLK_ENABLE();

  /*Configure GPIO pin Output Level */
  HAL_GPIO_WritePin(GPIOE, CLR_LED_4_Pin|CLR_INT_3_Pin|CLR_LED_3_Pin|RR_ARRAY_MUX_3_Pin
                          |RR_ARRAY_MUX_4_Pin|TOF_LPIN_1_Pin|TOF_INT_6_Pin|CLR_LED_2_Pin, GPIO_PIN_RESET);

  /*Configure GPIO pin Output Level */
  HAL_GPIO_WritePin(GPIOC, RR_ARRAY_ODD_Pin|RR_ARRAY_EVEN_Pin|FR_ARRAY_EVEN_Pin, GPIO_PIN_RESET);

  /*Configure GPIO pin Output Level */
  HAL_GPIO_WritePin(GPIOB, RR_ARRAY_MUX_1_Pin|RR_ARRAY_MUX_2_Pin|FR_INA_Pin|FR_INB_Pin
                          |RR_INA_Pin|RR_INB_Pin|LCD_DS_Pin|LCD_RESET_Pin
                          |LCD_CS_Pin, GPIO_PIN_RESET);

  /*Configure GPIO pin Output Level */
  HAL_GPIO_WritePin(GPIOD, TOF_LPIN_5_Pin|TOF_LPIN_4_Pin|TOF_LPIN_3_Pin|FR_ARRAY_SB2_Pin
                          |FR_ARRAY_SB3_Pin|FR_ARRAY_SB0_Pin|FR_ARRAY_SB1_Pin|FR_ARRAY_SA0_Pin
                          |FR_ARRAY_SA1_Pin|FR_ARRAY_SA2_Pin|FR_ARRAY_SA3_Pin, GPIO_PIN_RESET);

  /*Configure GPIO pin Output Level */
  HAL_GPIO_WritePin(GPIOA, TOF_LPIN_2_Pin|CLR_LED_1_Pin|FR_ARRAY_ODD_Pin, GPIO_PIN_RESET);

  /*Configure GPIO pins : CLR_INT_4_Pin IMU_INT_Pin TOF_INT_1_Pin TOF_LPIN_6_Pin
                           CLR_INT_2_Pin */
  GPIO_InitStruct.Pin = CLR_INT_4_Pin|IMU_INT_Pin|TOF_INT_1_Pin|TOF_LPIN_6_Pin
                          |CLR_INT_2_Pin;
  GPIO_InitStruct.Mode = GPIO_MODE_IT_RISING;
  GPIO_InitStruct.Pull = GPIO_NOPULL;
  HAL_GPIO_Init(GPIOE, &GPIO_InitStruct);

  /*Configure GPIO pins : CLR_LED_4_Pin CLR_INT_3_Pin CLR_LED_3_Pin RR_ARRAY_MUX_3_Pin
                           RR_ARRAY_MUX_4_Pin TOF_LPIN_1_Pin TOF_INT_6_Pin CLR_LED_2_Pin */
  GPIO_InitStruct.Pin = CLR_LED_4_Pin|CLR_INT_3_Pin|CLR_LED_3_Pin|RR_ARRAY_MUX_3_Pin
                          |RR_ARRAY_MUX_4_Pin|TOF_LPIN_1_Pin|TOF_INT_6_Pin|CLR_LED_2_Pin;
  GPIO_InitStruct.Mode = GPIO_MODE_OUTPUT_PP;
  GPIO_InitStruct.Pull = GPIO_NOPULL;
  GPIO_InitStruct.Speed = GPIO_SPEED_FREQ_LOW;
  HAL_GPIO_Init(GPIOE, &GPIO_InitStruct);

  /*Configure GPIO pins : PROX_IN_Pin TOF_INT_2_Pin CLR_INT_1_Pin */
  GPIO_InitStruct.Pin = PROX_IN_Pin|TOF_INT_2_Pin|CLR_INT_1_Pin;
  GPIO_InitStruct.Mode = GPIO_MODE_IT_RISING;
  GPIO_InitStruct.Pull = GPIO_NOPULL;
  HAL_GPIO_Init(GPIOA, &GPIO_InitStruct);

  /*Configure GPIO pins : RR_ARRAY_ODD_Pin RR_ARRAY_EVEN_Pin FR_ARRAY_EVEN_Pin */
  GPIO_InitStruct.Pin = RR_ARRAY_ODD_Pin|RR_ARRAY_EVEN_Pin|FR_ARRAY_EVEN_Pin;
  GPIO_InitStruct.Mode = GPIO_MODE_OUTPUT_PP;
  GPIO_InitStruct.Pull = GPIO_NOPULL;
  GPIO_InitStruct.Speed = GPIO_SPEED_FREQ_LOW;
  HAL_GPIO_Init(GPIOC, &GPIO_InitStruct);

  /*Configure GPIO pins : RR_ARRAY_MUX_1_Pin RR_ARRAY_MUX_2_Pin FR_INA_Pin FR_INB_Pin
                           RR_INA_Pin RR_INB_Pin LCD_DS_Pin LCD_RESET_Pin
                           LCD_CS_Pin */
  GPIO_InitStruct.Pin = RR_ARRAY_MUX_1_Pin|RR_ARRAY_MUX_2_Pin|FR_INA_Pin|FR_INB_Pin
                          |RR_INA_Pin|RR_INB_Pin|LCD_DS_Pin|LCD_RESET_Pin
                          |LCD_CS_Pin;
  GPIO_InitStruct.Mode = GPIO_MODE_OUTPUT_PP;
  GPIO_InitStruct.Pull = GPIO_NOPULL;
  GPIO_InitStruct.Speed = GPIO_SPEED_FREQ_LOW;
  HAL_GPIO_Init(GPIOB, &GPIO_InitStruct);

  /*Configure GPIO pins : TOF_LPIN_5_Pin TOF_LPIN_4_Pin TOF_LPIN_3_Pin FR_ARRAY_SB2_Pin
                           FR_ARRAY_SB3_Pin FR_ARRAY_SB0_Pin FR_ARRAY_SB1_Pin FR_ARRAY_SA0_Pin
                           FR_ARRAY_SA1_Pin FR_ARRAY_SA2_Pin FR_ARRAY_SA3_Pin */
  GPIO_InitStruct.Pin = TOF_LPIN_5_Pin|TOF_LPIN_4_Pin|TOF_LPIN_3_Pin|FR_ARRAY_SB2_Pin
                          |FR_ARRAY_SB3_Pin|FR_ARRAY_SB0_Pin|FR_ARRAY_SB1_Pin|FR_ARRAY_SA0_Pin
                          |FR_ARRAY_SA1_Pin|FR_ARRAY_SA2_Pin|FR_ARRAY_SA3_Pin;
  GPIO_InitStruct.Mode = GPIO_MODE_OUTPUT_PP;
  GPIO_InitStruct.Pull = GPIO_NOPULL;
  GPIO_InitStruct.Speed = GPIO_SPEED_FREQ_LOW;
  HAL_GPIO_Init(GPIOD, &GPIO_InitStruct);

  /*Configure GPIO pins : TOF_INT_5_Pin TOF_INT_4_Pin TOF_INT_3_Pin */
  GPIO_InitStruct.Pin = TOF_INT_5_Pin|TOF_INT_4_Pin|TOF_INT_3_Pin;
  GPIO_InitStruct.Mode = GPIO_MODE_IT_RISING;
  GPIO_InitStruct.Pull = GPIO_NOPULL;
  HAL_GPIO_Init(GPIOD, &GPIO_InitStruct);

  /*Configure GPIO pins : TOF_LPIN_2_Pin CLR_LED_1_Pin FR_ARRAY_ODD_Pin */
  GPIO_InitStruct.Pin = TOF_LPIN_2_Pin|CLR_LED_1_Pin|FR_ARRAY_ODD_Pin;
  GPIO_InitStruct.Mode = GPIO_MODE_OUTPUT_PP;
  GPIO_InitStruct.Pull = GPIO_NOPULL;
  GPIO_InitStruct.Speed = GPIO_SPEED_FREQ_LOW;
  HAL_GPIO_Init(GPIOA, &GPIO_InitStruct);

}

void Error_Handler(void)
{
  __disable_irq();
  while (1)
  {
  }
}
